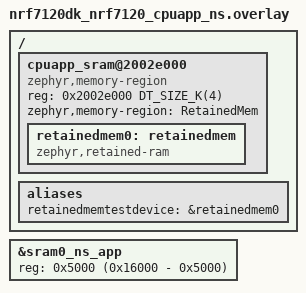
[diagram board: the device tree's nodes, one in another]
/ {
	cpuapp_sram@2002e000 {
		compatible = "zephyr,memory-region", "mmio-sram";
		reg = <0x2002e000 DT_SIZE_K(4)>;
		zephyr,memory-region = "RetainedMem";
		status = "okay";

		retainedmem0: retainedmem {
			compatible = "zephyr,retained-ram";
			status = "okay";
		};
	};

	aliases {
		retainedmemtestdevice = &retainedmem0;
	};
};

/* End zephyr,sram at the retained RAM, 0x2002e000 (sram0_ns + 0x16000) */
&sram0_ns_app {
	reg = <0x5000 (0x16000 - 0x5000)>;
};
